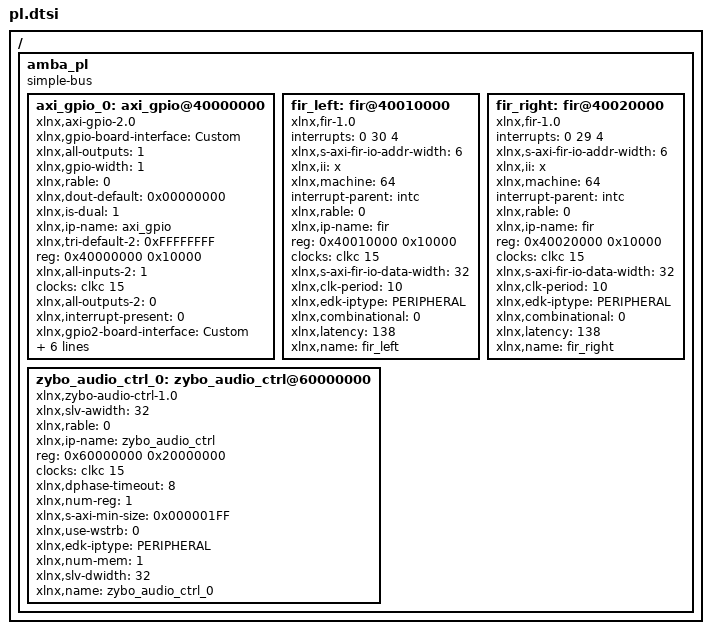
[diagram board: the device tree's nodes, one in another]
/ {
	amba_pl: amba_pl {
		ranges;
		compatible = "simple-bus";
		#address-cells = <1>;
		#size-cells = <1>;
		axi_gpio_0: axi_gpio@40000000 {
			xlnx,gpio-board-interface = "Custom";
			compatible = "xlnx,axi-gpio-2.0" , "xlnx,xps-gpio-1.00.a";
			xlnx,all-outputs = <1>;
			xlnx,gpio-width = <1>;
			xlnx,rable = <0>;
			xlnx,dout-default = <0x00000000>;
			xlnx,is-dual = <1>;
			xlnx,ip-name = "axi_gpio";
			xlnx,tri-default-2 = <0xFFFFFFFF>;
			reg = <0x40000000 0x10000>;
			xlnx,all-inputs-2 = <1>;
			clocks = <&clkc 15>;
			xlnx,all-outputs-2 = <0>;
			xlnx,interrupt-present = <0>;
			xlnx,gpio2-board-interface = "Custom";
			xlnx,edk-iptype = "PERIPHERAL";
			xlnx,dout-default-2 = <0x00000000>;
			xlnx,gpio2-width = <1>;
			status = "okay";
			clock-names = "s_axi_aclk";
			xlnx,tri-default = <0xFFFFFFFF>;
			xlnx,name = "axi_gpio_0";
			xlnx,all-inputs = <0>;
		};
		fir_left: fir@40010000 {
			interrupts = < 0 30 4 >;
			xlnx,s-axi-fir-io-addr-width = <6>;
			compatible = "xlnx,fir-1.0";
			xlnx,ii = "x";
			xlnx,machine = <64>;
			interrupt-parent = <&intc>;
			xlnx,rable = <0>;
			xlnx,ip-name = "fir";
			reg = <0x40010000 0x10000>;
			clocks = <&clkc 15>;
			xlnx,s-axi-fir-io-data-width = <32>;
			xlnx,clk-period = <10>;
			xlnx,edk-iptype = "PERIPHERAL";
			status = "okay";
			clock-names = "ap_clk";
			interrupt-names = "interrupt";
			xlnx,combinational = <0>;
			xlnx,latency = <138>;
			xlnx,name = "fir_left";
		};
		fir_right: fir@40020000 {
			interrupts = < 0 29 4 >;
			xlnx,s-axi-fir-io-addr-width = <6>;
			compatible = "xlnx,fir-1.0";
			xlnx,ii = "x";
			xlnx,machine = <64>;
			interrupt-parent = <&intc>;
			xlnx,rable = <0>;
			xlnx,ip-name = "fir";
			reg = <0x40020000 0x10000>;
			clocks = <&clkc 15>;
			xlnx,s-axi-fir-io-data-width = <32>;
			xlnx,clk-period = <10>;
			xlnx,edk-iptype = "PERIPHERAL";
			status = "okay";
			clock-names = "ap_clk";
			interrupt-names = "interrupt";
			xlnx,combinational = <0>;
			xlnx,latency = <138>;
			xlnx,name = "fir_right";
		};
		zybo_audio_ctrl_0: zybo_audio_ctrl@60000000 {
			compatible = "xlnx,zybo-audio-ctrl-1.0";
			xlnx,slv-awidth = <32>;
			xlnx,rable = <0>;
			xlnx,ip-name = "zybo_audio_ctrl";
			reg = <0x60000000 0x20000000>;
			clocks = <&clkc 15>;
			xlnx,dphase-timeout = <8>;
			xlnx,num-reg = <1>;
			xlnx,s-axi-min-size = <0x000001FF>;
			xlnx,use-wstrb = <0>;
			xlnx,edk-iptype = "PERIPHERAL";
			xlnx,num-mem = <1>;
			xlnx,slv-dwidth = <32>;
			status = "okay";
			clock-names = "S_AXI_ACLK";
			xlnx,name = "zybo_audio_ctrl_0";
		};
	};
};
